VERSION ""

NS_ :

BS_:

BU_: PDM ECU

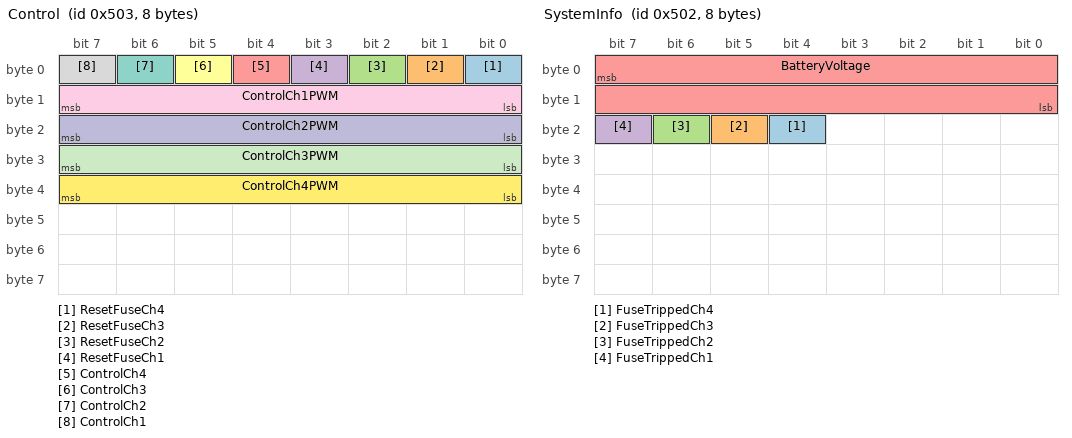
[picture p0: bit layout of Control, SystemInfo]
BO_ 1283 Control: 8 ECU
 SG_ ResetFuseCh4 : 0|1@0+ (1,0) [0|1] "" Vector__XXX
 SG_ ResetFuseCh3 : 1|1@0+ (1,0) [0|1] "" Vector__XXX
 SG_ ResetFuseCh2 : 2|1@0+ (1,0) [0|1] "" Vector__XXX
 SG_ ResetFuseCh1 : 3|1@0+ (1,0) [0|1] "" Vector__XXX
 SG_ ControlCh4 : 4|1@0+ (1,0) [0|1] "" Vector__XXX
 SG_ ControlCh3 : 5|1@0+ (1,0) [0|1] "" Vector__XXX
 SG_ ControlCh2 : 6|1@0+ (1,0) [0|1] "" Vector__XXX
 SG_ ControlCh1 : 7|1@0+ (1,0) [0|1] "" Vector__XXX
 SG_ ControlCh1PWM : 15|8@0+ (0.39215686275,0) [0|100] "%" Vector__XXX
 SG_ ControlCh2PWM : 23|8@0+ (0.39215686275,0) [0|100] "%" Vector__XXX
 SG_ ControlCh3PWM : 31|8@0+ (0.39215686275,0) [0|100] "%" Vector__XXX
 SG_ ControlCh4PWM : 39|8@0+ (0.39215686275,0) [0|100] "%" Vector__XXX

BO_ 1282 SystemInfo: 8 PDM
 SG_ FuseTrippedCh4 : 20|1@0+ (1,0) [0|1] "" Vector__XXX
 SG_ FuseTrippedCh3 : 21|1@0+ (1,0) [0|1] "" Vector__XXX
 SG_ FuseTrippedCh2 : 22|1@0+ (1,0) [0|1] "" Vector__XXX
 SG_ FuseTrippedCh1 : 23|1@0+ (1,0) [0|1] "" Vector__XXX
 SG_ BatteryVoltage : 7|16@0- (0.0239257812,0) [0|24.5] "Volt" Vector__XXX

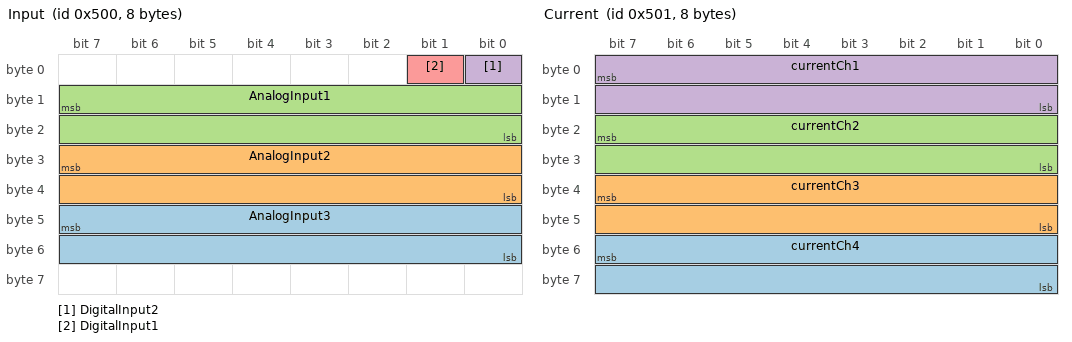
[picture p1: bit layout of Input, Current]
BO_ 1280 Input: 8 PDM
 SG_ AnalogInput3 : 47|16@0- (0.09765625,0) [0|100] "%" Vector__XXX
 SG_ AnalogInput2 : 31|16@0- (0.09765625,0) [0|100] "%" Vector__XXX
 SG_ AnalogInput1 : 15|16@0- (0.09765625,0) [0|100] "%" Vector__XXX
 SG_ DigitalInput2 : 0|1@0+ (1,0) [0|1] "" Vector__XXX
 SG_ DigitalInput1 : 1|1@0+ (1,0) [0|1] "" Vector__XXX

BO_ 1281 Current: 8 PDM
 SG_ currentCh4 : 55|16@0- (1,0) [0|0] "mA" Vector__XXX
 SG_ currentCh3 : 39|16@0- (1,0) [0|0] "mA" Vector__XXX
 SG_ currentCh2 : 23|16@0- (1,0) [0|0] "mA" Vector__XXX
 SG_ currentCh1 : 7|16@0- (1,0) [0|0] "mA" Vector__XXX

EV_ fuseStatus: 0 [0|1] "" 0 1 DUMMY_NODE_VECTOR0  Vector__XXX;

CM_ SG_ 1283 ControlCh1PWM "PWM Control channel 1, subordinate to signal ControlCh1";
CM_ SG_ 1283 ControlCh2PWM "PWM Control channel 2, subordinate to signal ControlCh2";
CM_ SG_ 1283 ControlCh3PWM "PWM Control channel 2, subordinate to signal ControlCh2";
CM_ SG_ 1283 ControlCh4PWM "Channel 4 does not support PWM, send 100% to turn it on. PWM Control channel 4, subordinate to signal ControlCh4";
CM_ BO_ 1282 "General information sent from PDM";
CM_ BO_ 1280 "DI and AN input channels from PDM";
CM_ BO_ 1281 "Main output channels current measurement";
BA_DEF_ BO_  "J1939PgAppearanceOnBus" ENUM  "Default","CAN_Extended","CANFD_Extended";
BA_DEF_ BO_  "J1939CPgSendTimeout" INT -1 3600000;
BA_DEF_ BO_  "J1939CPgTOS" INT 0 7;
BA_DEF_ BU_  "J1939MultiPgSendTimeout" INT 0 3600000;
BA_DEF_ BU_  "J1939MultiPgSizeThreshold" INT 0 64;
BA_DEF_ BU_  "J1939MultiPgBroadcastType" ENUM  "FBFF","FEFF";
BA_DEF_ SG_  "SigType" ENUM  "Default","Range","RangeSigned","ASCII","Discrete","Control","ReferencePGN","DTC","StringDelimiter","StringLength","StringLengthControl","MessageCounter","MessageChecksum";
BA_DEF_ SG_  "GenSigILSupport" ENUM  "No","Yes";
BA_DEF_ SG_  "GenSigSendType" ENUM  "Cyclic","OnWrite","OnWriteWithRepetition","OnChange","OnChangeWithRepetition","IfActive","IfActiveWithRepetition","NoSigSendType";
BA_DEF_ BO_  "GenMsgILSupport" ENUM  "No","Yes";
BA_DEF_ BU_  "NmStationAddress" INT 0 255;
BA_DEF_ BO_  "GenMsgSendType" ENUM  "cyclic","NotUsed","NotUsed","NotUsed","NotUsed","NotUsed","NotUsed","IfActive","noMsgSendType";
BA_DEF_ BO_  "GenMsgRequestable" INT 0 1;
BA_DEF_  "DBName" STRING ;
BA_DEF_  "BusType" STRING ;
BA_DEF_  "ProtocolType" STRING ;
BA_DEF_ BO_  "VFrameFormat" ENUM  "StandardCAN","ExtendedCAN","reserved","J1939PG","reserved","reserved","reserved","reserved","reserved","reserved","reserved","reserved","reserved","reserved","StandardCAN_FD","ExtendedCAN_FD";
BA_DEF_DEF_  "J1939PgAppearanceOnBus" "Default";
BA_DEF_DEF_  "J1939CPgSendTimeout" -1;
BA_DEF_DEF_  "J1939CPgTOS" 2;
BA_DEF_DEF_  "J1939MultiPgSendTimeout" 2;
BA_DEF_DEF_  "J1939MultiPgSizeThreshold" 56;
BA_DEF_DEF_  "J1939MultiPgBroadcastType" "FBFF";
BA_DEF_DEF_  "SigType" "Default";
BA_DEF_DEF_  "GenSigILSupport" "Yes";
BA_DEF_DEF_  "GenSigSendType" "NoSigSendType";
BA_DEF_DEF_  "GenMsgILSupport" "Yes";
BA_DEF_DEF_  "NmStationAddress" 254;
BA_DEF_DEF_  "GenMsgSendType" "noMsgSendType";
BA_DEF_DEF_  "GenMsgRequestable" 1;
BA_DEF_DEF_  "DBName" "";
BA_DEF_DEF_  "BusType" "CAN";
BA_DEF_DEF_  "ProtocolType" "J1939";
BA_DEF_DEF_  "VFrameFormat" "J1939PG";
BA_ "DBName" "PDM";
BA_ "VFrameFormat" BO_ 1283 0;
BA_ "VFrameFormat" BO_ 1282 0;
BA_ "VFrameFormat" BO_ 1280 0;
BA_ "VFrameFormat" BO_ 1281 0;
VAL_ 1282 FuseTrippedCh4 0 "not tripped" 1 "tripped" ;
VAL_ 1282 FuseTrippedCh3 0 "not tripped" 1 "tripped" ;
VAL_ 1282 FuseTrippedCh2 0 "not tripped" 1 "tripped" ;
VAL_ 1282 FuseTrippedCh1 0 "not tripped" 1 "tripped" ;
VAL_ fuseStatus 0 "not tripped" 1 "tripped" ;
